# NUC200AE_v1 register map
File version: 1.0
Registers are 32-bit, read-write, reset 0x0 unless marked. A register's access mark holds for its fields unless they carry their own. Offsets are from the block's base; [hi:lo] are bit positions; {n}, {i} and the like mark numbered series.

## I2S — I2S Register Map
Base 0x401A0000
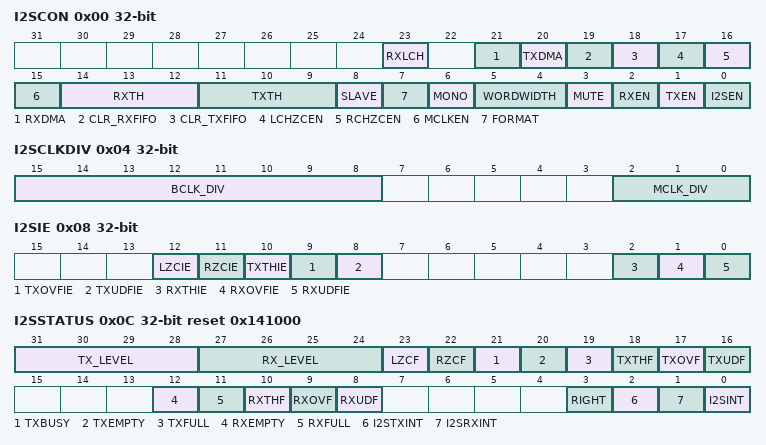
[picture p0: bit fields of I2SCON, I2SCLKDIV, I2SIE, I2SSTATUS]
0x00 I2SCON — I2S Control Register
  [23] RXLCH — Receive Left Channel Enable Bit
    0=Receive right channel data in Mono mode; 1=Receive left channel data in Mono mode
  [21] RXDMA — Receive DMA Enable Bit. When RX DMA is enabled, I2S requests DMA to transfer data from receive FIFO to SRAM if FIFO is not empty.
    0=RX DMA Disabled; 1=RX DMA Enabled
  [20] TXDMA — Transmit DMA Enable Bit. When TX DMA is enabled, I2S request DMA to transfer data from SRAM to transmit FIFO if FIFO is not full.
    0=TX DMA Disabled; 1=TX DMA Enabled
  [19] CLR_RXFIFO — Clear Receive FIFO. Write 1 to clear receive FIFO, internal pointer is reset to FIFO start point, and RX_LEVEL[3:0] returns 0 and receive FIFO becomes empty. This bit is cleared by hardware automatically. Returns 0 on read.
  [18] CLR_TXFIFO — Clear Transmit FIFO. Write 1 to clear transmit FIFO, internal pointer is reset to FIFO start point, and TX_LEVEL[3:0] returns to 0 and transmit FIFO becomes empty but data in transmit FIFO is not changed. This bit is cleared by hardware automatically. Returns 0 on read.
  [17] LCHZCEN — Left Channel Zero Cross Detection Enable Bit. If this bit is set to 1, when left channel data sign bit changes or next shift data bits are all 0 then LZCF flag in I2SSTATUS register is set to 1. This function is only available in transmit operation.
    0=Left channel zero cross detection Disabled; 1=Left channel zero cross detection Enabled
  [16] RCHZCEN — Right Channel Zero Cross Detection Enable Bit. If this bit is set to 1, when right channel data sign bit change or next shift data bits are all 0 then RZCF flag in I2SSTATUS register is set to 1. This function is only available in transmit operation.
    0=Right channel zero cross detection Disabled; 1=Right channel zero cross detection Enabled
  [15] MCLKEN — Master Clock Enable Bit. If MCLKEN is set to 1, I2S controller will generate master clock on I2S_MCLK pin for external audio devices.
    0=Master clock Disabled; 1=Master clock Enabled
  [14:12] RXTH — Receive FIFO Threshold Level. When the count of received data word(s) in buffer is equal to or higher than threshold level, RXTHF (I2SSTATUS[10]) will be set.
    {v}={v+1} word data in receive FIFO (v=0..7)
  [11:9] TXTH — Transmit FIFO Threshold Level. If the count of remaining data word (32 bits) in transmit FIFO is equal to or less than threshold level then TXTHF (I2SSTATUS[18]) is set.
    0=0 word data in transmit FIFO; 1=1 word data in transmit FIFO; {v}={v} words data in transmit FIFO (v=2..7)
  [8] SLAVE — Slave Mode. I2S can operate as master or slave. For Master mode, I2S_BCLK and I2S_LRCLK pins are output mode and send bit clock from NuMicro( NUC230/240 series to Audio CODEC chip. In Slave mode, I2S_BCLK and I2S_LRCLK pins are input mode and I2S_BCLK and I2S_LRCLK signals are received from outer Audio CODEC chip.
    0=Master mode; 1=Slave mode
  [7] FORMAT — Data Format
    0=I2S data format; 1=MSB justified data format
  [6] MONO — Monaural Data
    0=Data is stereo format; 1=Data is monaural format
  [5:4] WORDWIDTH
    0=data is 8-bit word; 1=data is 16-bit word; 2=data is 24-bit word; 3=data is 32-bit word
  [3] MUTE — Transmit Mute Enable Bit
    0=Transmit data is shifted from buffer; 1=Send zero on transmit channel
  [2] RXEN — Receive Enable Bit
    0=Data receiving Disabled; 1=Data receiving Enabled
  [1] TXEN — Transmit Enable Bit
    0=Data transmit Disabled; 1=Data transmit Enabled
  [0] I2SEN — I2S Controller Enable Bit
    0=Disabled; 1=Enabled
0x04 I2SCLKDIV — I2S Clock Divider Control Register
  [15:8] BCLK_DIV — Bit Clock Divider. The I2S controller will generate bit clock in Master mode. The bit clock rate, F_BCLK, is determined by the following expression.
  [2:0] MCLK_DIV — Master Clock Divider. If MCLKEN is set to 1, I2S controller will generate master clock for external audio devices. The master clock rate, F_MCLK, is determined by the following expressions. F_I2SCLK is the frequency of I2S peripheral clock. In general, the master clock rate is 256 times sampling clock rate.
0x08 I2SIE — I2S Interrupt Enable Register
  [all] fields
    0=Interrupt Disabled; 1=Interrupt Enabled
  [12] LZCIE — Left Channel Zero-Cross Interrupt Enable Bit. Interrupt occurs if this bit is set to 1 and left channel zero-cross event is detected.
  [11] RZCIE — Right Channel Zero-Cross Interrupt Enable Bit. Interrupt occurs if this bit is set to 1 and right channel zero-cross event is detected.
  [10] TXTHIE — Transmit FIFO Threshold Level Interrupt Enable Bit. Interrupt occurs if this bit is set to 1 and the count of data words in transmit FIFO is less than TXTH (I2SCON[11:9]).
  [9] TXOVFIE — Transmit FIFO Overflow Interrupt Enable Bit. Interrupt occurs if this bit is set to 1 and the transmit FIFO overflow flag is set to 1
  [8] TXUDFIE — Transmit FIFO Underflow Interrupt Enable Bit. Interrupt occurs if this bit is set to 1 and the transmit FIFO underflow flag is set to 1.
  [2] RXTHIE — Receive FIFO Threshold Level Interrupt Enable Bit. When the count of data words in receive FIFO is equal to or higher than RXTH (I2SCON[14:12]) and this bit is set to 1, receive FIFO threshold level interrupt will be asserted.
  [1] RXOVFIE — Receive FIFO Overflow Interrupt Enable Bit
  [0] RXUDFIE — Receive FIFO Underflow Interrupt Enable Bit
0x0C I2SSTATUS reset 0x141000
  [31:28] TX_LEVEL — Transmit FIFO Level. These bits indicate word number in transmit FIFO
    0=No data; 1=1 word in transmit FIFO; 8=8 words in transmit FIFO
  [27:24] RX_LEVEL — Receive FIFO Level. These bits indicate word number in receive FIFO
    0=No data; 1=1 word in receive FIFO; 8=8 words in receive FIFO
  [23] LZCF — Left Channel Zero-Cross Flag. It indicates the sign bit of left channel sample data is changed or all data bits are 0. Note: Write 1 to clear this bit to 0.
    0=No zero-cross; 1=Left channel zero-cross event is detected
  [22] RZCF — Right Channel Zero-Cross Flag. It indicates the sign bit of right channel sample data is changed or all data bits are 0. Note: Write 1 to clear this bit to 0.
    0=No zero-cross; 1=Right channel zero-cross event is detected
  [21] TXBUSY — Transmit Busy. This bit is cleared to 0 when all data in transmit FIFO and shift buffer is shifted out. And set to 1 when 1st data is load to shift buffer. Note: This bit is read only.
    0=Transmit shift buffer is empty; 1=Transmit shift buffer is not empty
  [20] TXEMPTY — Transmit FIFO Empty. This bit reflects data word number in transmit FIFO is 0. Note: This bit is read only.
    0=Not empty; 1=Empty
  [19] TXFULL — Transmit FIFO Full. This bit reflects data word number in transmit FIFO is 8. Note: This bit is read only.
    0=Not full; 1=Full
  [18] TXTHF — Transmit FIFO Threshold Flag. When the count of data stored in transmit-FIFO is equal to or less than threshold value set in TXTH (I2SCON[11:9]). The TXTHF bit becomes to 1. It keeps at 1 till TX_LEVEL (I2SSTATUS[31:28]) is larger than TXTH. Note: This bit is read only.
    0=Data word(s) in FIFO is larger than threshold level; 1=Data word(s) in FIFO is equal to or less than threshold level
  [17] TXOVF — Transmit FIFO Overflow Flag. This bit will be set to 1 if writes data to transmit FIFO when transmit FIFO is full. Note: Write 1 to clear this bit to 0.
    0=No overflow; 1=Overflow
  [16] TXUDF — Transmit FIFO Underflow Flag. If transmit FIFO is empty and hardware reads data from transmit FIFO. This bit will be set to 1. Note: Software can write 1 to clear this bit to 0.
    0=No underflow; 1=Underflow
  [12] RXEMPTY — Receive FIFO Empty. This bit reflects the count of data in receive FIFO is 0. Note: This bit is read only.
    0=Not empty; 1=Empty
  [11] RXFULL — Receive FIFO Full. This bit reflects the count of data in receive FIFO is 8. Note: This bit is read only.
    0=Not full; 1=Full
  [10] RXTHF — Receive FIFO Threshold Flag. When data word(s) in receive FIFO is equal to or larger than threshold value set in RXTH (I2SCON[14:12]). The RXTHF bit becomes to 1. It keeps at 1 till RX_LEVEL (I2SSTATUS[27:24]) is less than RXTH. Note: This bit is read only.
    0=Data word(s) in FIFO is less than threshold level; 1=Data word(s) in FIFO is equal to or larger than threshold level
  [9] RXOVF — Receive FIFO Overflow Flag. When receive FIFO is full and hardware attempt to write data to receive FIFO, this bit will be set to 1, data in 1st buffer will be overwrote. Note: Write 1 to clear this bit to 0.
    0=No overflow; 1=Overflow
  [8] RXUDF — Receive FIFO Underflow Flag. Underflow event will occur if read the empty receive FIFO. Note: Write 1 to clear this bit to 0.
    0=No underflow event occurred; 1=Underflow
  [3] RIGHT — Right Channel. This bit indicates current transmit data is belong to which channel. Note: This bit is read only.
    0=Left channel; 1=Right channel
  [2] I2STXINT — I2S Transmit Interrupt. Note: This bit is read only.
    0=No transmit interrupt; 1=Transmit interrupt
  [1] I2SRXINT — I2S Receive Interrupt. Note: This bit is read only.
    0=No receive interrupt; 1=Receive interrupt
  [0] I2SINT — I2S Interrupt Flag. This bit is wire-OR of I2STXINT and I2SRXINT bits. Note: This bit is read only.
    0=No I2S interrupt; 1=I2S interrupt
0x10 I2STXFIFO wo — I2S Transmit FIFO Register
  [31:0] TXFIFO — Transmit FIFO Register. I2S contains 8 words (8x32 bits) data buffer for data transmit. Write data to this register to prepare data for transmission. The remaining word number is indicated by TX_LEVEL (I2SSTATUS[31:28])
0x14 I2SRXFIFO ro — I2S Receive FIFO Register
  [31:0] RXFIFO — Receive FIFO Register. I2S contains 8 words (8x32 bits) data buffer for data receive. Read this register to get data of receive FIFO. The remaining data word number is indicated by RX_LEVEL (I2SSTATUS[27:24]).
